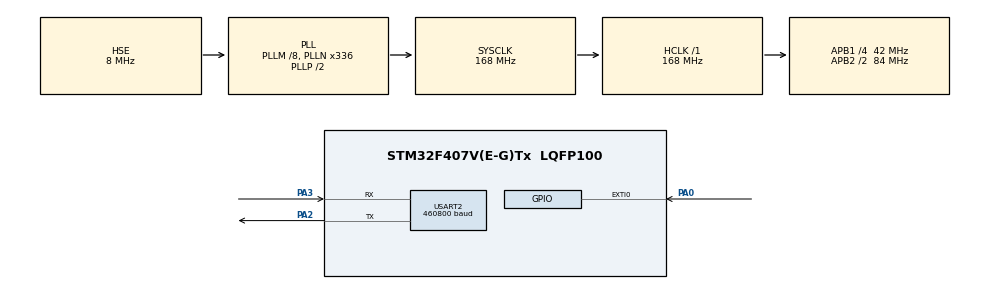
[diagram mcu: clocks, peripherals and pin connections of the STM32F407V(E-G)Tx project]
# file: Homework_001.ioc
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Dma.Request0=USART2_TX
Dma.Request1=USART2_RX
Dma.USART2_RX.1.Direction=DMA_PERIPH_TO_MEMORY
Dma.USART2_RX.1.FIFOMode=DMA_FIFOMODE_DISABLE
Dma.USART2_RX.1.Instance=DMA1_Stream5
Dma.USART2_RX.1.MemDataAlignment=DMA_MDATAALIGN_BYTE
Dma.USART2_RX.1.MemInc=DMA_MINC_ENABLE
Dma.USART2_RX.1.Mode=DMA_NORMAL
Dma.USART2_RX.1.PeriphDataAlignment=DMA_PDATAALIGN_BYTE
Dma.USART2_RX.1.PeriphInc=DMA_PINC_DISABLE
Dma.USART2_RX.1.Priority=DMA_PRIORITY_HIGH
Dma.USART2_TX.0.Direction=DMA_MEMORY_TO_PERIPH
Dma.USART2_TX.0.FIFOMode=DMA_FIFOMODE_DISABLE
Dma.USART2_TX.0.Instance=DMA1_Stream6
Dma.USART2_TX.0.MemDataAlignment=DMA_MDATAALIGN_BYTE
Dma.USART2_TX.0.MemInc=DMA_MINC_ENABLE
Dma.USART2_TX.0.Mode=DMA_NORMAL
Dma.USART2_TX.0.PeriphDataAlignment=DMA_PDATAALIGN_BYTE
Dma.USART2_TX.0.PeriphInc=DMA_PINC_DISABLE
Dma.USART2_TX.0.Priority=DMA_PRIORITY_HIGH
FREERTOS.Tasks01=UartTxTask,8,768,StartUartTxTask,Default,NULL,Dynamic,NULL,NULL;TelemetryTask,40,768,StartTelemetryTask,Default,NULL,Dynamic,NULL,NULL;ButtonTask,24,768,StartButtonTask,Default,NULL,Dynamic,NULL,NULL
FREERTOS.configUSE_NEWLIB_REENTRANT=1
Mcu.Family=STM32F4
Mcu.Name=STM32F407V(E-G)Tx
Mcu.Package=LQFP100
NVIC.DMA1_Stream5_IRQn=true\:5\:0\:false\:false\:true\:true\:false\:true\:true
NVIC.DMA1_Stream6_IRQn=true\:5\:0\:false\:false\:true\:true\:false\:true\:true
NVIC.PriorityGroup=NVIC_PRIORITYGROUP_4
NVIC.TIM3_IRQn=true\:15\:0\:false\:false\:true\:false\:false\:true\:true
NVIC.TimeBase=TIM3_IRQn
NVIC.TimeBaseIP=TIM3
NVIC.USART2_IRQn=true\:5\:0\:false\:false\:true\:true\:true\:true\:true
PA0-WKUP.Signal=GPXTI0
PA13.Mode=Serial_Wire
PA13.Signal=SYS_JTMS-SWDIO
PA14.Mode=Serial_Wire
PA14.Signal=SYS_JTCK-SWCLK
PA2.Mode=Asynchronous
PA2.Signal=USART2_TX
PA3.Mode=Asynchronous
PA3.Signal=USART2_RX
PH0-OSC_IN.Mode=HSE-External-Oscillator
PH0-OSC_IN.Signal=RCC_OSC_IN
PH1-OSC_OUT.Mode=HSE-External-Oscillator
PH1-OSC_OUT.Signal=RCC_OSC_OUT
ProjectManager.HeapSize=0x200
ProjectManager.StackSize=0x400
ProjectManager.TargetToolchain=STM32CubeIDE
RCC.48MHZClocksFreq_Value=48000000
RCC.AHBFreq_Value=168000000
RCC.APB1CLKDivider=RCC_HCLK_DIV4
RCC.APB1Freq_Value=42000000
RCC.APB1TimFreq_Value=84000000
RCC.APB2CLKDivider=RCC_HCLK_DIV2
RCC.APB2Freq_Value=84000000
RCC.APB2TimFreq_Value=168000000
RCC.CortexFreq_Value=168000000
RCC.HCLKFreq_Value=168000000
RCC.HSE_VALUE=8000000
RCC.HSI_VALUE=16000000
RCC.PLLM=8
RCC.PLLN=336
RCC.PLLQ=7
RCC.PLLSourceVirtual=RCC_PLLSOURCE_HSE
RCC.SYSCLKFreq_VALUE=168000000
RCC.SYSCLKSource=RCC_SYSCLKSOURCE_PLLCLK
RCC.VCOOutputFreq_Value=336000000
USART2.VirtualMode=VM_ASYNC
VP_FREERTOS_VS_CMSIS_V2.Mode=CMSIS_V2
VP_SYS_VS_tim3.Mode=TIM3
board=STM32F407G-DISC1
FREERTOS.configTOTAL_HEAP_SIZE=32768
TIM5.ClockDivision=TIM_CLOCKDIVISION_DIV1
TIM5.CounterMode=TIM_COUNTERMODE_UP
TIM5.Period=4294967295
TIM5.Prescaler=83
VP_TIM5_VS_ClockSourceINT.Mode=Internal
NVIC.EXTI0_IRQn=true\:5\:0\:false\:false\:true\:true\:true\:true\:true
USART2.BaudRate=460800

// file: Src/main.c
/* USER CODE BEGIN Header */
/**
  ******************************************************************************
  * @file           : main.c
  * @brief          : Main program body
  ******************************************************************************
  * @attention
  *
  * Copyright (c) 2026 STMicroelectronics.
  * All rights reserved.
  *
  * This software is licensed under terms that can be found in the LICENSE file
  * in the root directory of this software component.
  * If no LICENSE file comes with this software, it is provided AS-IS.
  *
  ******************************************************************************
  */
/* USER CODE END Header */
#include "main.h"
#include "cmsis_os.h"
#include "dma.h"
#include "usart.h"
#include "gpio.h"
#include "tim.h"

/* USER CODE BEGIN Includes */
#include "app.h"

/* USER CODE END Includes */

void SystemClock_Config(void);
void MX_FREERTOS_Init(void);

int main(void)
{

  /* MCU Configuration--------------------------------------------------------*/

  /* Reset of all peripherals, Initializes the Flash interface and the Systick. */
  HAL_Init();

  /* Configure the system clock */
  SystemClock_Config();

  /* Initialize all configured peripherals */
  MX_GPIO_Init();
  MX_DMA_Init();
  MX_USART2_UART_Init();
  MX_TIM5_Init();

  /* Init scheduler */
  osKernelInitialize();  /* Call init function for freertos objects (in cmsis_os2.c) */
  MX_FREERTOS_Init();

  /* Start scheduler */
  osKernelStart();

  /* We should never get here as control is now taken by the scheduler */

  /* Infinite loop */
  while (1)
  {

  }
}

void SystemClock_Config(void)
{
  RCC_OscInitTypeDef RCC_OscInitStruct = {0};
  RCC_ClkInitTypeDef RCC_ClkInitStruct = {0};

  /** Configure the main internal regulator output voltage
  */
  __HAL_RCC_PWR_CLK_ENABLE();
  __HAL_PWR_VOLTAGESCALING_CONFIG(PWR_REGULATOR_VOLTAGE_SCALE1);

  /** Initializes the RCC Oscillators according to the specified parameters
  * in the RCC_OscInitTypeDef structure.
  */
  RCC_OscInitStruct.OscillatorType = RCC_OSCILLATORTYPE_HSE;
  RCC_OscInitStruct.HSEState = RCC_HSE_ON;
  RCC_OscInitStruct.PLL.PLLState = RCC_PLL_ON;
  RCC_OscInitStruct.PLL.PLLSource = RCC_PLLSOURCE_HSE;
  RCC_OscInitStruct.PLL.PLLM = 8;
  RCC_OscInitStruct.PLL.PLLN = 336;
  RCC_OscInitStruct.PLL.PLLP = RCC_PLLP_DIV2;
  RCC_OscInitStruct.PLL.PLLQ = 7;
  if (HAL_RCC_OscConfig(&RCC_OscInitStruct) != HAL_OK)
  {
    Error_Handler();
  }

  /** Initializes the CPU, AHB and APB buses clocks
  */
  RCC_ClkInitStruct.ClockType = RCC_CLOCKTYPE_HCLK|RCC_CLOCKTYPE_SYSCLK
                              |RCC_CLOCKTYPE_PCLK1|RCC_CLOCKTYPE_PCLK2;
  RCC_ClkInitStruct.SYSCLKSource = RCC_SYSCLKSOURCE_PLLCLK;
  RCC_ClkInitStruct.AHBCLKDivider = RCC_SYSCLK_DIV1;
  RCC_ClkInitStruct.APB1CLKDivider = RCC_HCLK_DIV4;
  RCC_ClkInitStruct.APB2CLKDivider = RCC_HCLK_DIV2;

  if (HAL_RCC_ClockConfig(&RCC_ClkInitStruct, FLASH_LATENCY_5) != HAL_OK)
  {
    Error_Handler();
  }
}

void HAL_TIM_PeriodElapsedCallback(TIM_HandleTypeDef *htim)
{
  if (htim->Instance == TIM3)
  {
    HAL_IncTick();
  }
}

void Error_Handler(void)
{
  __disable_irq();
  while (1)
  {
  }
}

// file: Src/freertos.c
/* USER CODE BEGIN Header */
/**
  ******************************************************************************
  * File Name          : freertos.c
  * Description        : Code for freertos applications
  ******************************************************************************
  * @attention
  *
  * Copyright (c) 2026 STMicroelectronics.
  * All rights reserved.
  *
  * This software is licensed under terms that can be found in the LICENSE file
  * in the root directory of this software component.
  * If no LICENSE file comes with this software, it is provided AS-IS.
  *
  ******************************************************************************
  */
/* USER CODE END Header */

#include "FreeRTOS.h"
#include "task.h"
#include "main.h"
#include "cmsis_os.h"

/* USER CODE BEGIN Includes */
#include "app.h"

/* USER CODE END Includes */

/* Definitions for UartTxTask */
osThreadId_t UartTxTaskHandle;
const osThreadAttr_t UartTxTask_attributes = {
  .name = "UartTxTask",
  .stack_size = 768 * 4,
  .priority = (osPriority_t) osPriorityLow,
};
/* Definitions for TelemetryTask */
osThreadId_t TelemetryTaskHandle;
const osThreadAttr_t TelemetryTask_attributes = {
  .name = "TelemetryTask",
  .stack_size = 768 * 4,
  .priority = (osPriority_t) osPriorityHigh,
};
/* Definitions for ButtonTask */
osThreadId_t ButtonTaskHandle;
const osThreadAttr_t ButtonTask_attributes = {
  .name = "ButtonTask",
  .stack_size = 768 * 4,
  .priority = (osPriority_t) osPriorityNormal,
};

void StartUartTxTask(void *argument);
void StartTelemetryTask(void *argument);
void StartButtonTask(void *argument);

void MX_FREERTOS_Init(void); /* (MISRA C 2004 rule 8.1) */

void MX_FREERTOS_Init(void) {

  /* USER CODE BEGIN RTOS_QUEUES */
  App_Init();
  /* add queues, ... */
  /* USER CODE END RTOS_QUEUES */

  /* Create the thread(s) */
  /* creation of UartTxTask */
  UartTxTaskHandle = osThreadNew(StartUartTxTask, NULL, &UartTxTask_attributes);

  /* creation of TelemetryTask */
  TelemetryTaskHandle = osThreadNew(StartTelemetryTask, NULL, &TelemetryTask_attributes);

  /* creation of ButtonTask */
  ButtonTaskHandle = osThreadNew(StartButtonTask, NULL, &ButtonTask_attributes);

  /* USER CODE BEGIN RTOS_THREADS */
  configASSERT(UartTxTaskHandle && TelemetryTaskHandle && ButtonTaskHandle);
  vTaskPrioritySet((TaskHandle_t)TelemetryTaskHandle, 3);
  vTaskPrioritySet((TaskHandle_t)ButtonTaskHandle, 2);
  vTaskPrioritySet((TaskHandle_t)UartTxTaskHandle, 1);
  /* add threads, ... */
  /* USER CODE END RTOS_THREADS */

}

void StartUartTxTask(void *argument)
{
  /* USER CODE BEGIN StartUartTxTask */
  (void)argument;
  App_UartTask();
  /* USER CODE END StartUartTxTask */
}

void StartTelemetryTask(void *argument)
{
  /* USER CODE BEGIN StartTelemetryTask */
  (void)argument;
  App_TelemetryTask();
  /* USER CODE END StartTelemetryTask */
}

void StartButtonTask(void *argument)
{
  /* USER CODE BEGIN StartButtonTask */
  (void)argument;
  App_ButtonTask();
  /* USER CODE END StartButtonTask */
}
